AUTOSAR XML (schema 4-3-0)
package /Impl_UART_ARPkg
  swc implementation Impl_SWC_UART_type: programming-language=C, sw-version=1.0.0, vendor-id=0, behavior=SWC_UART_type_IB
    code-descriptors:
      code SRC: artifact-descriptors=autosar-engineering-object={short-label=EngObject, category=SWSRC}
    resource consumption ResourceConsumption
      memory section Mem_SWC_UART_CODE: size=0, sw-addrmethod=CODE, symbol=CODE
package /Interface_UART_ARPkg
  client server interface IF_UARTCDD
    operation CSOP_UART_Console
package /SWC_UART_ARPkg
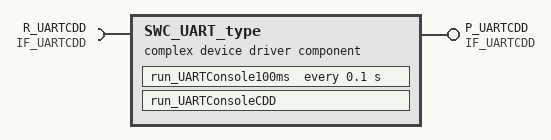
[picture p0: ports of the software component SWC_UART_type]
  complex device driver sw component type SWC_UART_type
    provide port P_UARTCDD: provided-interface=IF_UARTCDD
    require port R_UARTCDD: required-interface=IF_UARTCDD
    behavior SWC_UART_type_IB: handle-termination-and-restart=NO-SUPPORT, port-api-option{enable-take-address=false, indirect-api=false, port=P_UARTCDD}
      timing event TE_UART_100ms: start-on-event=run_UARTConsole100ms, period=0.1
      operation invoked event oie_P_UARTCDD_CSOP_UART_Console: start-on-event=run_UARTConsoleCDD, operation=P_UARTCDD.CSOP_UART_Console
      runnable run_UARTConsole100ms
        sync call scp_CSOP_UART_Console: operation=R_UARTCDD.CSOP_UART_Console, timeout=0.0
      runnable run_UARTConsoleCDD
